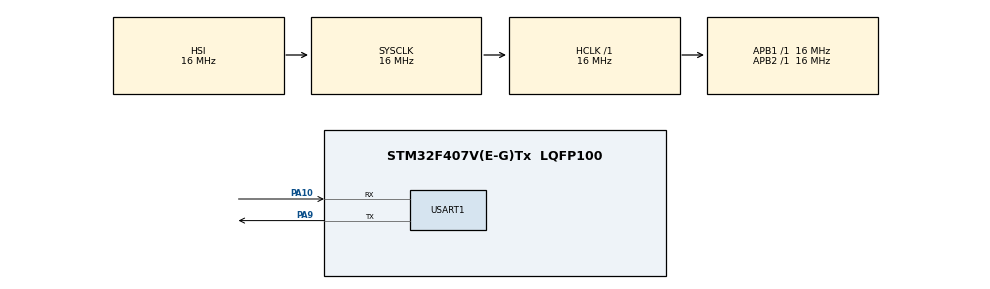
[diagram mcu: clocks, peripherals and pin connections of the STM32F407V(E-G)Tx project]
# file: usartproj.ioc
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FREERTOS.Tasks01=defaultTask,24,128,StartDefaultTask,Default,NULL,Dynamic,NULL,NULL
FREERTOS.configUSE_NEWLIB_REENTRANT=1
Mcu.Family=STM32F4
Mcu.Name=STM32F407V(E-G)Tx
Mcu.Package=LQFP100
NVIC.PriorityGroup=NVIC_PRIORITYGROUP_4
NVIC.TIM2_IRQn=true\:15\:0\:false\:false\:true\:false\:false\:true\:true
NVIC.TimeBase=TIM2_IRQn
NVIC.TimeBaseIP=TIM2
PA10.Mode=Asynchronous
PA10.Signal=USART1_RX
PA9.Mode=Asynchronous
PA9.Signal=USART1_TX
ProjectManager.HeapSize=0x200
ProjectManager.StackSize=0x400
ProjectManager.TargetToolchain=STM32CubeIDE
RCC.AHBFreq_Value=16000000
RCC.APB1Freq_Value=16000000
RCC.APB2Freq_Value=16000000
RCC.CortexFreq_Value=16000000
RCC.HSE_VALUE=25000000
RCC.HSI_VALUE=16000000
RCC.LSE_VALUE=32768
RCC.SYSCLKFreq_VALUE=16000000
RCC.VCOOutputFreq_Value=192000000
USART1.VirtualMode=VM_ASYNC
VP_FREERTOS_VS_CMSIS_V2.Mode=CMSIS_V2
VP_SYS_VS_tim2.Mode=TIM2
board=custom

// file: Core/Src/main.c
/* USER CODE BEGIN Header */
/**
  ******************************************************************************
  * @file           : main.c
  * @brief          : Main program body
  ******************************************************************************
  * @attention
  *
  * Copyright (c) 2025 STMicroelectronics.
  * All rights reserved.
  *
  * This software is licensed under terms that can be found in the LICENSE file
  * in the root directory of this software component.
  * If no LICENSE file comes with this software, it is provided AS-IS.
  *
  ******************************************************************************
  */
/* USER CODE END Header */

#include "main.h"
#include "cmsis_os.h"
#include "task.h"
#include "semphr.h"

/* USER CODE BEGIN Includes */
UART_HandleTypeDef huart1;
SemaphoreHandle_t uartMutex;
/* USER CODE END Includes */

void SystemClock_Config(void);
static void MX_GPIO_Init(void);
static void MX_USART1_UART_Init(void);
void StartDefaultTask(void *argument);

/* USER CODE BEGIN PFP */
void UART_Transmit(char *data);
char UART_Receive(void);
void TransmitTask(void *argument);
void ReceiveTask(void *argument);
/* USER CODE END PFP */

/* USER CODE BEGIN 0 */
void UART_Transmit(char *data) {
    xSemaphoreTake(uartMutex, portMAX_DELAY);
    HAL_UART_Transmit(&huart1, (uint8_t*)data, strlen(data), HAL_MAX_DELAY);
    xSemaphoreGive(uartMutex);
}

char UART_Receive(void) {
    char receivedData;
    xSemaphoreTake(uartMutex, portMAX_DELAY);
    while (!(USART1->SR & USART_SR_RXNE));
    receivedData = USART1->DR;
    xSemaphoreGive(uartMutex);
    return receivedData;
}

void TransmitTask(void *argument) {
    while (1) {
        UART_Transmit("Hello from TransmitTask!\r\n");
        vTaskDelay(pdMS_TO_TICKS(1000));
    }
}

void ReceiveTask(void *argument) {
    uint8_t rxBuffer[64];
    uint8_t rxByte;
    uint16_t index = 0;

    for (;;) {
        if (HAL_UART_Receive(&huart1, &rxByte, 1, 100) == HAL_OK) {
            // Check for message terminator
            if (rxByte == '\n' || index >= sizeof(rxBuffer)-1) {
                rxBuffer[index] = '\0'; // Null-terminate

                // Only process if it's not an ACK
                if (strstr((char*)rxBuffer, "ACK") == NULL) {
                    char msg[64];
                    sprintf(msg, "Complete Message: %s\r\n", rxBuffer);
                    UART_Transmit(msg);
                }
                index = 0; // Reset buffer
            } else {
                rxBuffer[index++] = rxByte;
            }
        }
        osDelay(1);
    }
}
/* USER CODE END 0 */

int main(void)
{
    /* MCU Configuration--------------------------------------------------------*/
    HAL_Init();
    SystemClock_Config();
    MX_GPIO_Init();
    MX_USART1_UART_Init();

    /* USER CODE BEGIN 2 */
    uartMutex = xSemaphoreCreateMutex();
    if (uartMutex == NULL) {
        Error_Handler();
    }
    /* USER CODE END 2 */

    /* Init scheduler */
    osKernelInitialize();

    /* Create the thread(s) */
    /* creation of defaultTask */
    const osThreadAttr_t defaultTask_attributes = {
        .name = "defaultTask",
        .stack_size = 128 * 4,
        .priority = (osPriority_t) osPriorityNormal,
    };
    osThreadNew(StartDefaultTask, NULL, &defaultTask_attributes);

    /* USER CODE BEGIN RTOS_THREADS */
    xTaskCreate(TransmitTask, "TransmitTask", 128, NULL, 1, NULL);
    xTaskCreate(ReceiveTask, "ReceiveTask", 128, NULL, 1, NULL);
    /* USER CODE END RTOS_THREADS */

    /* Start scheduler */
    osKernelStart();

    /* We should never get here as control is now taken by the scheduler */
    while (1) {}
}

void StartDefaultTask(void *argument)
{
    for(;;)
    {
        osDelay(1);
    }
}

void SystemClock_Config(void)
{
    RCC_OscInitTypeDef RCC_OscInitStruct = {0};
    RCC_ClkInitTypeDef RCC_ClkInitStruct = {0};

    /** Configure the main internal regulator output voltage */
    __HAL_RCC_PWR_CLK_ENABLE();
    __HAL_PWR_VOLTAGESCALING_CONFIG(PWR_REGULATOR_VOLTAGE_SCALE1);

    /** Initializes the RCC Oscillators according to the specified parameters */
    RCC_OscInitStruct.OscillatorType = RCC_OSCILLATORTYPE_HSI;
    RCC_OscInitStruct.HSIState = RCC_HSI_ON;
    RCC_OscInitStruct.HSICalibrationValue = RCC_HSICALIBRATION_DEFAULT;
    RCC_OscInitStruct.PLL.PLLState = RCC_PLL_NONE;
    if (HAL_RCC_OscConfig(&RCC_OscInitStruct) != HAL_OK) {
        Error_Handler();
    }

    /** Initializes the CPU, AHB and APB buses clocks */
    RCC_ClkInitStruct.ClockType = RCC_CLOCKTYPE_HCLK|RCC_CLOCKTYPE_SYSCLK
                                |RCC_CLOCKTYPE_PCLK1|RCC_CLOCKTYPE_PCLK2;
    RCC_ClkInitStruct.SYSCLKSource = RCC_SYSCLKSOURCE_HSI;
    RCC_ClkInitStruct.AHBCLKDivider = RCC_SYSCLK_DIV1;
    RCC_ClkInitStruct.APB1CLKDivider = RCC_HCLK_DIV1;
    RCC_ClkInitStruct.APB2CLKDivider = RCC_HCLK_DIV1;

    if (HAL_RCC_ClockConfig(&RCC_ClkInitStruct, FLASH_LATENCY_0) != HAL_OK) {
        Error_Handler();
    }
}

void MX_USART1_UART_Init(void)
{
    huart1.Instance = USART1;
    huart1.Init.BaudRate = 115200;
    huart1.Init.WordLength = UART_WORDLENGTH_8B;
    huart1.Init.StopBits = UART_STOPBITS_1;
    huart1.Init.Parity = UART_PARITY_NONE;
    huart1.Init.Mode = UART_MODE_TX_RX;
    huart1.Init.HwFlowCtl = UART_HWCONTROL_NONE;
    huart1.Init.OverSampling = UART_OVERSAMPLING_16;
    if (HAL_UART_Init(&huart1) != HAL_OK) {
        Error_Handler();
    }
}

void MX_GPIO_Init(void)
{
    __HAL_RCC_GPIOA_CLK_ENABLE();
}

void Error_Handler(void)
{
    __disable_irq();
    while (1) {}
}
